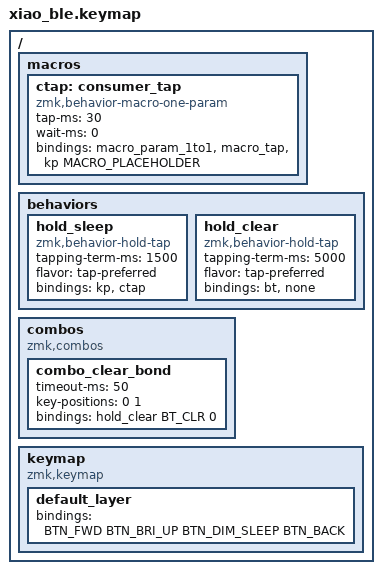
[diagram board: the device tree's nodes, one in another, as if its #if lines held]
#include <behaviors.dtsi>
#include <dt-bindings/zmk/keys.h>
#include <dt-bindings/zmk/bt.h>

/ {
    macros {
        /* 30 ms tap, same as the validated ESP32 test */
        ctap: consumer_tap {
            compatible = "zmk,behavior-macro-one-param";
            #binding-cells = <1>;
            tap-ms = <30>;
            wait-ms = <0>;
            bindings = <&macro_param_1to1>, <&macro_tap &kp MACRO_PLACEHOLDER>;
        };
    };

    behaviors {
        /* D_DOWN: tap = brightness down, hold 1.5 s = Kindle sleep */
        hold_sleep: hold_sleep {
            compatible = "zmk,behavior-hold-tap";
            #binding-cells = <2>;
            tapping-term-ms = <1500>;
            flavor = "tap-preferred";
            bindings = <&kp>, <&ctap>;
        };

        /* Clear the stored bond only after a 5 s hold, so a brief diagonal press does nothing */
        hold_clear: hold_clear {
            compatible = "zmk,behavior-hold-tap";
            #binding-cells = <2>;
            tapping-term-ms = <5000>;
            flavor = "tap-preferred";
            bindings = <&bt>, <&none>;
        };
    };

    /* D_UP + D_RIGHT (up-right diagonal) held 5 s: forget the paired Kindle so a new one can pair */
    combos {
        compatible = "zmk,combos";
        combo_clear_bond {
            timeout-ms = <50>;
            key-positions = <0 1>;
            bindings = <&hold_clear BT_CLR 0>;
        };
    };

    keymap {
        compatible = "zmk,keymap";

        default_layer {
#if defined(BTN_FWD)
            bindings = <BTN_FWD BTN_BRI_UP BTN_DIM_SLEEP BTN_BACK>;
#else
            bindings = <&kp PG_DN  &kp C_BRI_UP  &hold_sleep C_POWER C_BRI_DN  &kp PG_UP>;
#endif
        };
    };
};
